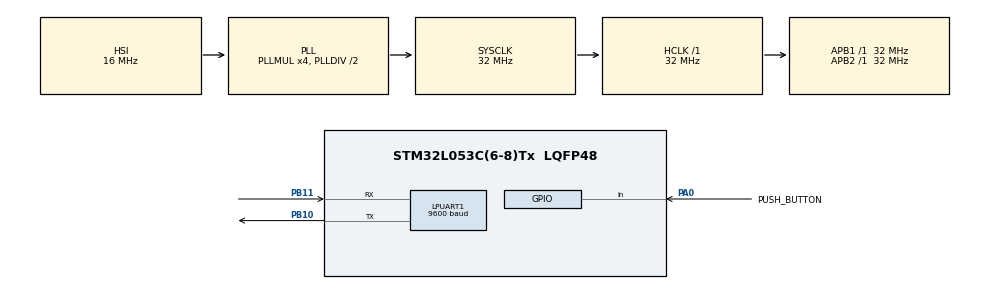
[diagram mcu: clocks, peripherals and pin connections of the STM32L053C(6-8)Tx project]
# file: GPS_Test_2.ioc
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LPUART1.BaudRate=9600
LPUART1.WordLength=UART_WORDLENGTH_8B
Mcu.Family=STM32L0
Mcu.Name=STM32L053C(6-8)Tx
Mcu.Package=LQFP48
NVIC.RNG_LPUART1_IRQn=true\:0\:0\:false\:false\:true\:true\:true
PA0.GPIO_Label=PUSH_BUTTON
PA0.Signal=GPIO_Input
PB10.Mode=Asynchronous
PB10.Signal=LPUART1_TX
PB11.Mode=Asynchronous
PB11.Signal=LPUART1_RX
ProjectManager.HeapSize=0x200
ProjectManager.StackSize=0x400
ProjectManager.TargetToolchain=TrueSTUDIO
RCC.AHBFreq_Value=32000000
RCC.APB1Freq_Value=32000000
RCC.APB1TimFreq_Value=32000000
RCC.APB2Freq_Value=32000000
RCC.APB2TimFreq_Value=32000000
RCC.HCLKFreq_Value=32000000
RCC.HSE_VALUE=8000000
RCC.HSI16_VALUE=16000000
RCC.HSI48_VALUE=48000000
RCC.HSI_VALUE=16000000
RCC.LSE_VALUE=32768
RCC.MSI_VALUE=2097000
RCC.PLLMUL=RCC_PLLMUL_4
RCC.SYSCLKFreq_VALUE=32000000
RCC.SYSCLKSource=RCC_SYSCLKSOURCE_PLLCLK
RCC.VCOOutputFreq_Value=64000000
board=custom

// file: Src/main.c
/* USER CODE BEGIN Header */
/**
  ******************************************************************************
  * @file           : main.c
  * @brief          : Main program body
  ******************************************************************************
  * @attention
  *
  * <h2><center>&copy; Copyright (c) 2020 STMicroelectronics.
  * All rights reserved.</center></h2>
  *
  * This software component is licensed by ST under BSD 3-Clause license,
  * the "License"; You may not use this file except in compliance with the
  * License. You may obtain a copy of the License at:
  *                        opensource.org/licenses/BSD-3-Clause
  *
  ******************************************************************************
  */
/* USER CODE END Header */

#include "main.h"
#include <stdio.h>
#include <string.h>

UART_HandleTypeDef hlpuart1;

void SystemClock_Config(void);
static void MX_GPIO_Init(void);
static void MX_LPUART1_UART_Init(void);

/* USER CODE BEGIN 0 */
uint8_t data[128] = {0};
uint8_t GPS_BAUDRATE[] = "$PMTK251,9600*17\r\n";
uint8_t GPS_FIXRATE[] = "$PMTK300,1000,0,0,0,0*1C\r\n";
uint8_t GPS_GGA[] = "$PMTK314,0,0,0,1,0,0,0,0,0,0,0,0,0,0,0,0,0,0,0*29\r\n";
uint8_t GPS_1HZ[] = "$PMTK220,1000*1F\r\n";
uint8_t GPS_STANDBY[] = "$PMTK161,0*28\r\n";

char GGA_MESSAGE[128];
char latitude[9];
char longitude[9];
char longDir[1];
char latDir[1];
char fix[1];

/* USER CODE END 0 */

int main(void)
{

  /* MCU Configuration--------------------------------------------------------*/

  /* Reset of all peripherals, Initializes the Flash interface and the Systick. */
  HAL_Init();

  /* Configure the system clock */
  SystemClock_Config();

  /* Initialize all configured peripherals */
  MX_GPIO_Init();
  MX_LPUART1_UART_Init();
  /* USER CODE BEGIN 2 */

  HAL_UART_Transmit(&hlpuart1, GPS_BAUDRATE, sizeof(GPS_BAUDRATE), 1000); //set baud rate
  HAL_UART_Transmit(&hlpuart1, GPS_FIXRATE, sizeof(GPS_FIXRATE), 1000); //set fix rate
  HAL_UART_Transmit(&hlpuart1, GPS_1HZ, sizeof(GPS_1HZ), 1000); //set frequency
  HAL_UART_Transmit(&hlpuart1, GPS_GGA, sizeof(GPS_GGA), 1000); //set sentence format

  /* USER CODE END 2 */

  /* Infinite loop */
  while (1)
  {

    /* USER CODE BEGIN 3 */
    if (HAL_GPIO_ReadPin(GPIOA, GPIO_PIN_0)) {
    	HAL_UART_Receive_IT(&hlpuart1, data, sizeof(data));
    }
  }
  /* USER CODE END 3 */
}

void SystemClock_Config(void)
{
  RCC_OscInitTypeDef RCC_OscInitStruct = {0};
  RCC_ClkInitTypeDef RCC_ClkInitStruct = {0};
  RCC_PeriphCLKInitTypeDef PeriphClkInit = {0};

  /** Configure the main internal regulator output voltage
  */
  __HAL_PWR_VOLTAGESCALING_CONFIG(PWR_REGULATOR_VOLTAGE_SCALE1);
  /** Initializes the CPU, AHB and APB busses clocks
  */
  RCC_OscInitStruct.OscillatorType = RCC_OSCILLATORTYPE_HSI;
  RCC_OscInitStruct.HSIState = RCC_HSI_ON;
  RCC_OscInitStruct.HSICalibrationValue = RCC_HSICALIBRATION_DEFAULT;
  RCC_OscInitStruct.PLL.PLLState = RCC_PLL_ON;
  RCC_OscInitStruct.PLL.PLLSource = RCC_PLLSOURCE_HSI;
  RCC_OscInitStruct.PLL.PLLMUL = RCC_PLLMUL_4;
  RCC_OscInitStruct.PLL.PLLDIV = RCC_PLLDIV_2;
  if (HAL_RCC_OscConfig(&RCC_OscInitStruct) != HAL_OK)
  {
    Error_Handler();
  }
  /** Initializes the CPU, AHB and APB busses clocks
  */
  RCC_ClkInitStruct.ClockType = RCC_CLOCKTYPE_HCLK|RCC_CLOCKTYPE_SYSCLK
                              |RCC_CLOCKTYPE_PCLK1|RCC_CLOCKTYPE_PCLK2;
  RCC_ClkInitStruct.SYSCLKSource = RCC_SYSCLKSOURCE_PLLCLK;
  RCC_ClkInitStruct.AHBCLKDivider = RCC_SYSCLK_DIV1;
  RCC_ClkInitStruct.APB1CLKDivider = RCC_HCLK_DIV1;
  RCC_ClkInitStruct.APB2CLKDivider = RCC_HCLK_DIV1;

  if (HAL_RCC_ClockConfig(&RCC_ClkInitStruct, FLASH_LATENCY_1) != HAL_OK)
  {
    Error_Handler();
  }
  PeriphClkInit.PeriphClockSelection = RCC_PERIPHCLK_LPUART1;
  PeriphClkInit.Lpuart1ClockSelection = RCC_LPUART1CLKSOURCE_PCLK1;
  if (HAL_RCCEx_PeriphCLKConfig(&PeriphClkInit) != HAL_OK)
  {
    Error_Handler();
  }
}

static void MX_LPUART1_UART_Init(void)
{

  hlpuart1.Instance = LPUART1;
  hlpuart1.Init.BaudRate = 9600;
  hlpuart1.Init.WordLength = UART_WORDLENGTH_8B;
  hlpuart1.Init.StopBits = UART_STOPBITS_1;
  hlpuart1.Init.Parity = UART_PARITY_NONE;
  hlpuart1.Init.Mode = UART_MODE_TX_RX;
  hlpuart1.Init.HwFlowCtl = UART_HWCONTROL_NONE;
  hlpuart1.Init.OneBitSampling = UART_ONE_BIT_SAMPLE_DISABLE;
  hlpuart1.AdvancedInit.AdvFeatureInit = UART_ADVFEATURE_NO_INIT;
  if (HAL_UART_Init(&hlpuart1) != HAL_OK)
  {
    Error_Handler();
  }

}

static void MX_GPIO_Init(void)
{
  GPIO_InitTypeDef GPIO_InitStruct = {0};

  /* GPIO Ports Clock Enable */
  __HAL_RCC_GPIOA_CLK_ENABLE();
  __HAL_RCC_GPIOB_CLK_ENABLE();

  /*Configure GPIO pin : PUSH_BUTTON_Pin */
  GPIO_InitStruct.Pin = PUSH_BUTTON_Pin;
  GPIO_InitStruct.Mode = GPIO_MODE_INPUT;
  GPIO_InitStruct.Pull = GPIO_NOPULL;
  HAL_GPIO_Init(PUSH_BUTTON_GPIO_Port, &GPIO_InitStruct);

}

/* USER CODE BEGIN 4 */
void HAL_UART_RxCpltCallback(UART_HandleTypeDef *huart)
{
	//pause interrupts

	char string[7];
	int commaCnt = 0;
	int i = 0;
	int j = 0;

	memcpy(string, data, 6);

	if(!strcmp(string, "$GPGGA"))
	{
		i = 6; //since valid message type, start one character after "A"
		while(data[i] != '\n')
		{
			if (data[i] == ',')
			{
				commaCnt++; //increase number of commas found
				j = 0; //reset counter for parsing
			}
			else
			{
				if(commaCnt == 2) //latitude
				{
					latitude[j] = data[i];
					j++;
				}
				else if(commaCnt == 3) //latitude direction
				{
					latDir[j] = data[i];
					j++;
				}
				else if(commaCnt == 4) //longitude
				{
					longitude[j] = data[i];
					j++;
				}
				else if(commaCnt == 5) //longitude direction
				{
					longDir[j] = data[i];
					j++;
				}
				else if(commaCnt == 6)
				{
					fix[j] = data[i];
					j++;
				}
			}
			i++; //increase element counter
		}

		if((fix[0] == 0) || (commaCnt != 14)) //no fix
		{
			HAL_UART_Receive_IT(&hlpuart1, data, sizeof(data)); //receive another message
		}

	}
	else
	{
		HAL_UART_Receive_IT(&hlpuart1, data, sizeof(data));
	}

	//unpause interrupts

}
/* USER CODE END 4 */

void Error_Handler(void)
{
}

/************************ (C) COPYRIGHT STMicroelectronics *****END OF FILE****/
